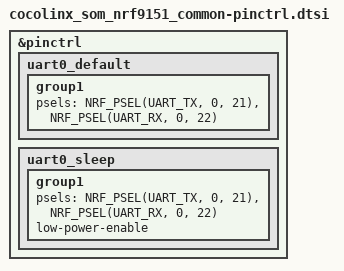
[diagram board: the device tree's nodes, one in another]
/*
 * Copyright (c) 2025 cocolinx
 * SPDX-License-Identifier: Apache-2.0
 */

&pinctrl {
	uart0_default: uart0_default {
		group1 {
			psels = <NRF_PSEL(UART_TX, 0, 21)>, // 21
					<NRF_PSEL(UART_RX, 0, 22)>; // 22
		};
	};
	uart0_sleep: uart0_sleep {
		group1 {
			psels = <NRF_PSEL(UART_TX, 0, 21)>,
					<NRF_PSEL(UART_RX, 0, 22)>;
			low-power-enable;
		};
	};
};
